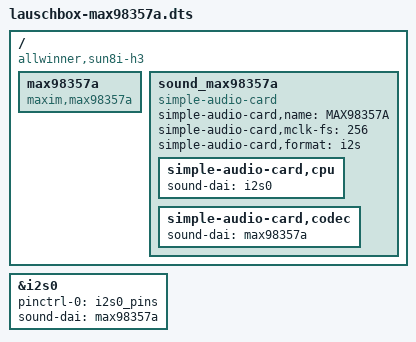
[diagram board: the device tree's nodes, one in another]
/*
 * Verstärker MAX98357A an I2S0 des Allwinner H3 (Banana Pi M2 Zero), für Armbian.
 *
 *   BCLK = PA19 (Pin 27), LRC = PA18 (Pin 28), DIN = PA20 (Pin 40)
 *
 * Die Soundkarte heißt „MAX98357A“ wie beim Raspberry Pi; go-librespot und mpv nutzen plughw:CARD=MAX98357A.
 * Den SD-Pin (Stummschaltung) steuert die Box-Software selbst über PL4 (Pin 36), deshalb kein sdmode-gpios hier.
 * Eingerichtet von box/install.sh mit: sudo armbian-add-overlay box/overlays/lauschbox-max98357a.dts
 * Nach dem Vorbild von github.com/sonocotta/orange-pi-media-center (Orange Pi One, ebenfalls H3).
 */
/dts-v1/;
/plugin/;

/ {
	compatible = "allwinner,sun8i-h3";

	fragment@0 {
		target-path = "/";
		__overlay__ {
			max98357a: max98357a {
				#sound-dai-cells = <0>;
				compatible = "maxim,max98357a";
				status = "okay";
			};
		};
	};

	fragment@1 {
		target = <&i2s0>;
		__overlay__ {
			status = "okay";
			pinctrl-names = "default";
			pinctrl-0 = <&i2s0_pins>;
			sound-dai = <&max98357a>;
		};
	};

	fragment@2 {
		target-path = "/";
		__overlay__ {
			sound_max98357a {
				compatible = "simple-audio-card";
				simple-audio-card,name = "MAX98357A";
				simple-audio-card,mclk-fs = <256>;
				simple-audio-card,format = "i2s";
				status = "okay";

				simple-audio-card,cpu {
					sound-dai = <&i2s0>;
				};

				simple-audio-card,codec {
					sound-dai = <&max98357a>;
				};
			};
		};
	};
};
